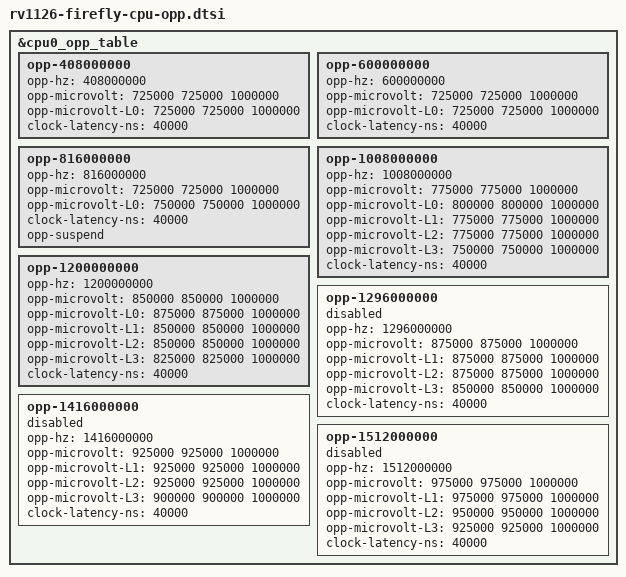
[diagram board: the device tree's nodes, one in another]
&cpu0_opp_table {

	opp-408000000 {
		opp-hz = /bits/ 64 <408000000>;
		opp-microvolt = <725000 725000 1000000>;
		opp-microvolt-L0 = <725000 725000 1000000>;
		clock-latency-ns = <40000>;
	};
	opp-600000000 {
		opp-hz = /bits/ 64 <600000000>;
		opp-microvolt = <725000 725000 1000000>;
		opp-microvolt-L0 = <725000 725000 1000000>;
		clock-latency-ns = <40000>;
	};
	opp-816000000 {
		opp-hz = /bits/ 64 <816000000>;
		opp-microvolt = <725000 725000 1000000>;
		opp-microvolt-L0 = <750000 750000 1000000>;
		clock-latency-ns = <40000>;
		opp-suspend;
	};
	opp-1008000000 {
		opp-hz = /bits/ 64 <1008000000>;
		opp-microvolt = <775000 775000 1000000>;
		opp-microvolt-L0 = <800000 800000 1000000>;
		opp-microvolt-L1 = <775000 775000 1000000>;
		opp-microvolt-L2 = <775000 775000 1000000>;
		opp-microvolt-L3 = <750000 750000 1000000>;
		clock-latency-ns = <40000>;
	};
	opp-1200000000 {
		opp-hz = /bits/ 64 <1200000000>;
		opp-microvolt = <850000 850000 1000000>;
		opp-microvolt-L0 = <875000 875000 1000000>;
		opp-microvolt-L1 = <850000 850000 1000000>;
		opp-microvolt-L2 = <850000 850000 1000000>;
		opp-microvolt-L3 = <825000 825000 1000000>;
		clock-latency-ns = <40000>;
	};
	opp-1296000000 {
		status = "disabled";
		opp-hz = /bits/ 64 <1296000000>;
		opp-microvolt = <875000 875000 1000000>;
		opp-microvolt-L1 = <875000 875000 1000000>;
		opp-microvolt-L2 = <875000 875000 1000000>;
		opp-microvolt-L3 = <850000 850000 1000000>;
		clock-latency-ns = <40000>;
	};
	opp-1416000000 {
		status = "disabled";
		opp-hz = /bits/ 64 <1416000000>;
		opp-microvolt = <925000 925000 1000000>;
		opp-microvolt-L1 = <925000 925000 1000000>;
		opp-microvolt-L2 = <925000 925000 1000000>;
		opp-microvolt-L3 = <900000 900000 1000000>;
		clock-latency-ns = <40000>;
	};
	opp-1512000000 {
		status = "disabled";
		opp-hz = /bits/ 64 <1512000000>;
		opp-microvolt = <975000 975000 1000000>;
		opp-microvolt-L1 = <975000 975000 1000000>;
		opp-microvolt-L2 = <950000 950000 1000000>;
		opp-microvolt-L3 = <925000 925000 1000000>;
		clock-latency-ns = <40000>;
	};
};
